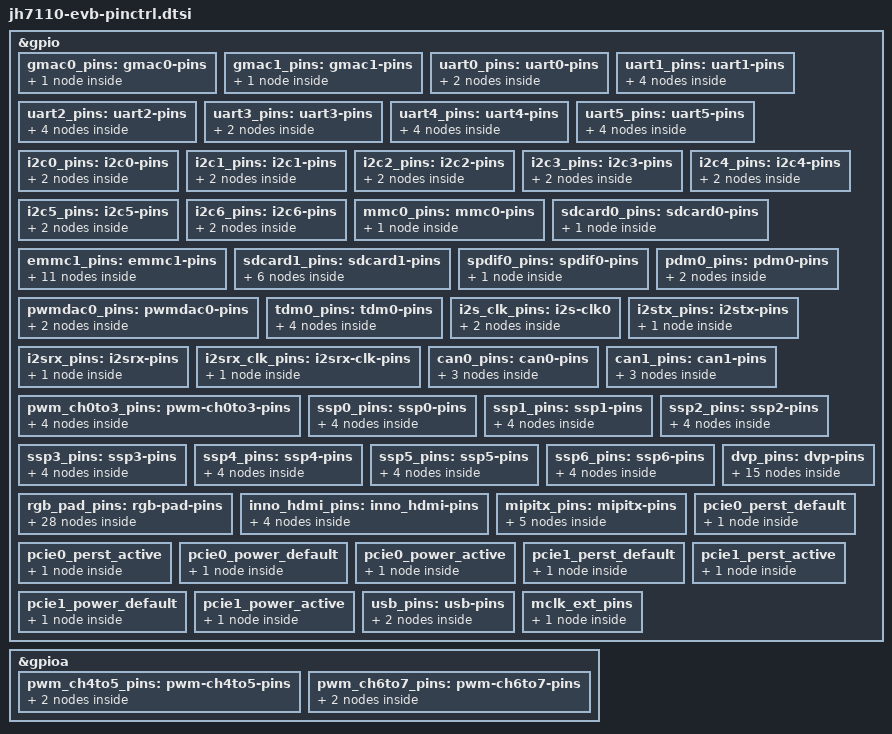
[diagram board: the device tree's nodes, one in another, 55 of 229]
// SPDX-License-Identifier: GPL-2.0 OR MIT
/*
 * Copyright (C) 2022 StarFive Technology Co., Ltd.
 */

#include <dt-bindings/gpio/gpio.h>
#include <dt-bindings/pinctrl/starfive,jh7110-pinfunc.h>

&gpio {
	gmac0_pins: gmac0-pins {
		gmac0-pins-reset {
			starfive,pins = <PAD_GPIO13>;
			starfive,pinmux = <PAD_GPIO13_FUNC_SEL 0>;
			starfive,pin-ioconfig = <IO(GPIO_IE(1) | (GPIO_PU(1)))>;
			starfive,pin-gpio-dout = <GPO_HIGH>;
			starfive,pin-gpio-doen = <OEN_LOW>;
		};
	};

	gmac1_pins: gmac1-pins {
		gmac1-pins0 {
			starfive,pins = <PAD_GMAC1_MDC>;
			starfive,pin-ioconfig = <IO(GPIO_IE(1)|GPIO_SMT(1) | GPIO_DS(3))>;
			starfive,pin-syscon = <PADCFG_PAD_GMAC1_MDC_SYSCON IO_3_3V>;
		};
	};

	uart0_pins: uart0-pins {
		uart0-pins-tx {
			starfive,pins = <PAD_GPIO5>;
			starfive,pin-ioconfig = <IO(GPIO_IE(1) | GPIO_DS(3))>;
			starfive,pin-gpio-dout = <GPO_UART0_SOUT>;
			starfive,pin-gpio-doen = <OEN_LOW>;
		};

		uart0-pins-rx {
			starfive,pins = <PAD_GPIO6>;
			starfive,pinmux = <PAD_GPIO6_FUNC_SEL 0>;
			starfive,pin-ioconfig = <IO(GPIO_IE(1) | GPIO_PU(1))>;
			starfive,pin-gpio-doen = <OEN_HIGH>;
			starfive,pin-gpio-din =  <GPI_UART0_SIN>;
		};
	};

	uart1_pins: uart1-pins {
		uart1-pins-tx {
			starfive,pins = <PAD_GPIO30>;
			starfive,pinmux = <PAD_GPIO30_FUNC_SEL 0>;
			starfive,pin-ioconfig = <IO(GPIO_IE(1) | GPIO_DS(3))>;
			starfive,pin-gpio-dout = <GPO_UART1_SOUT>;
			starfive,pin-gpio-doen = <OEN_LOW>;
		};

		uart1-pins-rx {
			starfive,pins = <PAD_GPIO31>;
			starfive,pinmux = <PAD_GPIO31_FUNC_SEL 0>;
			starfive,pin-ioconfig = <IO(GPIO_IE(1) | GPIO_PU(1))>;
			starfive,pin-gpio-doen = <OEN_HIGH>;
			starfive,pin-gpio-din =  <GPI_UART1_SIN>;
		};

		uart1-pins-cts {
			starfive,pins = <PAD_GPIO29>;
			starfive,pinmux = <PAD_GPIO29_FUNC_SEL 0>;
			starfive,pin-ioconfig = <IO(GPIO_IE(1))>;
			starfive,pin-gpio-doen = <OEN_HIGH>;
			starfive,pin-gpio-din =  <GPI_UART1_CTS_N>;
		};

		uart1-pins-rts {
			starfive,pins = <PAD_GPIO27>;
			starfive,pinmux = <PAD_GPIO27_FUNC_SEL 0>;
			starfive,pin-ioconfig = <IO(GPIO_IE(1))>;
			starfive,pin-gpio-dout = <GPO_UART1_RTS_N>;
			starfive,pin-gpio-doen = <OEN_LOW>;
		};
	};

	uart2_pins: uart2-pins {
		uart2-pins-tx {
			starfive,pins = <PAD_GPIO30>;
			starfive,pinmux = <PAD_GPIO30_FUNC_SEL 0>;
			starfive,pin-ioconfig = <IO(GPIO_IE(1) | GPIO_DS(3))>;
			starfive,pin-gpio-dout = <GPO_UART2_SOUT>;
			starfive,pin-gpio-doen = <OEN_LOW>;
		};

		uart2-pins-rx {
			starfive,pins = <PAD_GPIO31>;
			starfive,pinmux = <PAD_GPIO31_FUNC_SEL 0>;
			starfive,pin-ioconfig = <IO(GPIO_IE(1) | GPIO_PU(1))>;
			starfive,pin-gpio-doen = <OEN_HIGH>;
			starfive,pin-gpio-din =  <GPI_UART2_SIN>;
		};

		uart2-pins-cts {
			starfive,pins = <PAD_GPIO29>;
			starfive,pinmux = <PAD_GPIO29_FUNC_SEL 0>;
			starfive,pin-ioconfig = <IO(GPIO_IE(1))>;
			starfive,pin-gpio-doen = <OEN_HIGH>;
			starfive,pin-gpio-din =  <GPI_UART2_CTS_N>;
		};

		uart2-pins-rts {
			starfive,pins = <PAD_GPIO27>;
			starfive,pinmux = <PAD_GPIO27_FUNC_SEL 0>;
			starfive,pin-ioconfig = <IO(GPIO_IE(1))>;
			starfive,pin-gpio-dout = <GPO_UART2_RTS_N>;
			starfive,pin-gpio-doen = <OEN_LOW>;
		};
	};

	uart3_pins: uart3-pins {
		uart3-pins-tx {
			starfive,pins = <PAD_GPIO30>;
			starfive,pinmux = <PAD_GPIO30_FUNC_SEL 0>;
			starfive,pin-ioconfig = <IO(GPIO_IE(1) | GPIO_DS(3))>;
			starfive,pin-gpio-dout = <GPO_UART3_SOUT>;
			starfive,pin-gpio-doen = <OEN_LOW>;
		};

		uart3-pins-rx {
			starfive,pins = <PAD_GPIO31>;
			starfive,pinmux = <PAD_GPIO31_FUNC_SEL 0>;
			starfive,pin-ioconfig = <IO(GPIO_IE(1) | GPIO_PU(1))>;
			starfive,pin-gpio-doen = <OEN_HIGH>;
			starfive,pin-gpio-din =  <GPI_UART3_SIN>;
		};
	};

	uart4_pins: uart4-pins {
		uart4-pins-tx {
			starfive,pins = <PAD_GPIO30>;
			starfive,pinmux = <PAD_GPIO30_FUNC_SEL 0>;
			starfive,pin-ioconfig = <IO(GPIO_IE(1) | GPIO_DS(3))>;
			starfive,pin-gpio-dout = <GPO_UART4_SOUT>;
			starfive,pin-gpio-doen = <OEN_LOW>;
		};

		uart4-pins-rx {
			starfive,pins = <PAD_GPIO31>;
			starfive,pinmux = <PAD_GPIO31_FUNC_SEL 0>;
			starfive,pin-ioconfig = <IO(GPIO_IE(1) | GPIO_PU(1))>;
			starfive,pin-gpio-doen = <OEN_HIGH>;
			starfive,pin-gpio-din =  <GPI_UART4_SIN>;
		};

		uart4-pins-cts {
			starfive,pins = <PAD_GPIO29>;
			starfive,pinmux = <PAD_GPIO29_FUNC_SEL 0>;
			starfive,pin-ioconfig = <IO(GPIO_IE(1))>;
			starfive,pin-gpio-doen = <OEN_HIGH>;
			starfive,pin-gpio-din =  <GPI_UART4_CTS_N>;
		};

		uart4-pins-rts {
			starfive,pins = <PAD_GPIO27>;
			starfive,pinmux = <PAD_GPIO27_FUNC_SEL 0>;
			starfive,pin-ioconfig = <IO(GPIO_IE(1))>;
			starfive,pin-gpio-dout = <GPO_UART4_RTS_N>;
			starfive,pin-gpio-doen = <OEN_LOW>;
		};
	};

	uart5_pins: uart5-pins {
		uart5-pins-tx {
			starfive,pins = <PAD_GPIO30>;
			starfive,pinmux = <PAD_GPIO30_FUNC_SEL 0>;
			starfive,pin-ioconfig = <IO(GPIO_IE(1) | GPIO_DS(3))>;
			starfive,pin-gpio-dout = <GPO_UART5_SOUT>;
			starfive,pin-gpio-doen = <OEN_LOW>;
		};

		uart5-pins-rx {
			starfive,pins = <PAD_GPIO31>;
			starfive,pinmux = <PAD_GPIO31_FUNC_SEL 0>;
			starfive,pin-ioconfig = <IO(GPIO_IE(1) | GPIO_PU(1))>;
			starfive,pin-gpio-doen = <OEN_HIGH>;
			starfive,pin-gpio-din =  <GPI_UART5_SIN>;
		};

		uart5-pins-cts {
			starfive,pins = <PAD_GPIO29>;
			starfive,pinmux = <PAD_GPIO29_FUNC_SEL 0>;
			starfive,pin-ioconfig = <IO(GPIO_IE(1))>;
			starfive,pin-gpio-doen = <OEN_HIGH>;
			starfive,pin-gpio-din =  <GPI_UART5_CTS_N>;
		};

		uart5-pins-rts {
			starfive,pins = <PAD_GPIO27>;
			starfive,pinmux = <PAD_GPIO27_FUNC_SEL 0>;
			starfive,pin-ioconfig = <IO(GPIO_IE(1))>;
			starfive,pin-gpio-dout = <GPO_UART5_RTS_N>;
			starfive,pin-gpio-doen = <OEN_LOW>;
		};
	};

	i2c0_pins: i2c0-pins {
		i2c0-pins-scl {
			starfive,pins = <PAD_GPIO57>;
			starfive,pinmux = <PAD_GPIO57_FUNC_SEL 0>;
			starfive,pin-ioconfig = <IO(GPIO_IE(1) | (GPIO_PU(1)))>;
			starfive,pin-gpio-dout = <GPO_LOW>;
			starfive,pin-gpio-doen = <OEN_I2C0_IC_CLK_OE>;
			starfive,pin-gpio-din =  <GPI_I2C0_IC_CLK_IN_A>;
		};

		i2c0-pins-sda {
			starfive,pins = <PAD_GPIO58>;
			starfive,pinmux = <PAD_GPIO58_FUNC_SEL 0>;
			starfive,pin-ioconfig = <IO(GPIO_IE(1) | (GPIO_PU(1)))>;
			starfive,pin-gpio-dout = <GPO_LOW>;
			starfive,pin-gpio-doen = <OEN_I2C0_IC_DATA_OE>;
			starfive,pin-gpio-din =  <GPI_I2C0_IC_DATA_IN_A>;
		};
	};

	i2c1_pins: i2c1-pins {
		i2c1-pins-scl {
			starfive,pins = <PAD_GPIO49>;
			starfive,pinmux = <PAD_GPIO49_FUNC_SEL 0>;
			starfive,pin-ioconfig = <IO(GPIO_IE(1) | (GPIO_PU(1)))>;
			starfive,pin-gpio-dout = <GPO_LOW>;
			starfive,pin-gpio-doen = <OEN_I2C1_IC_CLK_OE>;
			starfive,pin-gpio-din =  <GPI_I2C1_IC_CLK_IN_A>;
		};

		i2c1-pins-sda {
			starfive,pins = <PAD_GPIO50>;
			starfive,pinmux = <PAD_GPIO50_FUNC_SEL 0>;
			starfive,pin-ioconfig = <IO(GPIO_IE(1) | (GPIO_PU(1)))>;
			starfive,pin-gpio-dout = <GPO_LOW>;
			starfive,pin-gpio-doen = <OEN_I2C1_IC_DATA_OE>;
			starfive,pin-gpio-din =  <GPI_I2C1_IC_DATA_IN_A>;
		};
	};

	i2c2_pins: i2c2-pins {
		i2c2-pins-scl {
			starfive,pins = <PAD_GPIO11>;
			starfive,pinmux = <PAD_GPIO11_FUNC_SEL 0>;
			starfive,pin-ioconfig = <IO(GPIO_IE(1) | (GPIO_PU(1)))>;
			starfive,pin-gpio-dout = <GPO_LOW>;
			starfive,pin-gpio-doen = <OEN_I2C2_IC_CLK_OE>;
			starfive,pin-gpio-din =  <GPI_I2C2_IC_CLK_IN_A>;
		};

		i2c2-pins-sda {
			starfive,pins = <PAD_GPIO9>;
			starfive,pinmux = <PAD_GPIO9_FUNC_SEL 0>;
			starfive,pin-ioconfig = <IO(GPIO_IE(1) | (GPIO_PU(1)))>;
			starfive,pin-gpio-dout = <GPO_LOW>;
			starfive,pin-gpio-doen = <OEN_I2C2_IC_DATA_OE>;
			starfive,pin-gpio-din =  <GPI_I2C2_IC_DATA_IN_A>;
		};
	};

	i2c3_pins: i2c3-pins {
		i2c3-pins-scl {
			starfive,pins = <PAD_GPIO51>;
			starfive,pinmux = <PAD_GPIO51_FUNC_SEL 0>;
			starfive,pin-ioconfig = <IO(GPIO_IE(1) | (GPIO_PU(1)))>;
			starfive,pin-gpio-dout = <GPO_LOW>;
			starfive,pin-gpio-doen = <OEN_I2C3_IC_CLK_OE>;
			starfive,pin-gpio-din =  <GPI_I2C3_IC_CLK_IN_A>;
		};

		i2c3-pins-sda {
			starfive,pins = <PAD_GPIO52>;
			starfive,pinmux = <PAD_GPIO52_FUNC_SEL 0>;
			starfive,pin-ioconfig = <IO(GPIO_IE(1) | (GPIO_PU(1)))>;
			starfive,pin-gpio-dout = <GPO_LOW>;
			starfive,pin-gpio-doen = <OEN_I2C3_IC_DATA_OE>;
			starfive,pin-gpio-din =  <GPI_I2C3_IC_DATA_IN_A>;
		};
	};

	i2c4_pins: i2c4-pins {
		i2c4-pins-scl {
			starfive,pins = <PAD_GPIO18>;
			starfive,pinmux = <PAD_GPIO18_FUNC_SEL 0>;
			starfive,pin-ioconfig = <IO(GPIO_IE(1) | (GPIO_PU(1)))>;
			starfive,pin-gpio-dout = <GPO_LOW>;
			starfive,pin-gpio-doen = <OEN_I2C4_IC_CLK_OE>;
			starfive,pin-gpio-din =  <GPI_I2C4_IC_CLK_IN_A>;
		};

		i2c4-pins-sda {
			starfive,pins = <PAD_GPIO12>;
			starfive,pinmux = <PAD_GPIO12_FUNC_SEL 0>;
			starfive,pin-ioconfig = <IO(GPIO_IE(1) | (GPIO_PU(1)))>;
			starfive,pin-gpio-dout = <GPO_LOW>;
			starfive,pin-gpio-doen = <OEN_I2C4_IC_DATA_OE>;
			starfive,pin-gpio-din =  <GPI_I2C4_IC_DATA_IN_A>;
		};
	};

	i2c5_pins: i2c5-pins {
		i2c5-pins-scl {
			starfive,pins = <PAD_GPIO19>;
			starfive,pinmux = <PAD_GPIO19_FUNC_SEL 0>;
			starfive,pin-ioconfig = <IO(GPIO_IE(1) | (GPIO_PU(1)))>;
			starfive,pin-gpio-dout = <GPO_LOW>;
			starfive,pin-gpio-doen = <OEN_I2C5_IC_CLK_OE>;
			starfive,pin-gpio-din =  <GPI_I2C5_IC_CLK_IN_A>;
		};

		i2c5-pins-sda {
			starfive,pins = <PAD_GPIO20>;
			starfive,pinmux = <PAD_GPIO20_FUNC_SEL 0>;
			starfive,pin-ioconfig = <IO(GPIO_IE(1) | (GPIO_PU(1)))>;
			starfive,pin-gpio-dout = <GPO_LOW>;
			starfive,pin-gpio-doen = <OEN_I2C5_IC_DATA_OE>;
			starfive,pin-gpio-din =  <GPI_I2C5_IC_DATA_IN_A>;
		};
	};

	i2c6_pins: i2c6-pins {
		i2c6-pins-scl {
			starfive,pins = <PAD_GPIO16>;
			starfive,pinmux = <PAD_GPIO16_FUNC_SEL 0>;
			starfive,pin-ioconfig = <IO(GPIO_IE(1) | (GPIO_PU(1)))>;
			starfive,pin-gpio-dout = <GPO_LOW>;
			starfive,pin-gpio-doen = <OEN_I2C6_IC_CLK_OE>;
			starfive,pin-gpio-din =  <GPI_I2C6_IC_CLK_IN_A>;
		};

		i2c6-pins-sda {
			starfive,pins = <PAD_GPIO17>;
			starfive,pinmux = <PAD_GPIO17_FUNC_SEL 0>;
			starfive,pin-ioconfig = <IO(GPIO_IE(1) | (GPIO_PU(1)))>;
			starfive,pin-gpio-dout = <GPO_LOW>;
			starfive,pin-gpio-doen = <OEN_I2C6_IC_DATA_OE>;
			starfive,pin-gpio-din =  <GPI_I2C6_IC_DATA_IN_A>;
		};
	};

	mmc0_pins: mmc0-pins {
		 mmc0-pins-rest {
			starfive,pins = <PAD_GPIO22>;
			starfive,pinmux = <PAD_GPIO22_FUNC_SEL 0>;
			starfive,pin-ioconfig = <IO(GPIO_IE(1) | (GPIO_PU(1)))>;
			starfive,pin-gpio-dout = <GPO_SDIO0_RST_N>;
			starfive,pin-gpio-doen = <OEN_LOW>;
		};
	};

	sdcard0_pins: sdcard0-pins {
		 sdcard0-pins-rest {
			starfive,pins = <PAD_GPIO24>;
			starfive,pinmux = <PAD_GPIO24_FUNC_SEL 0>;
			starfive,pin-ioconfig = <IO(GPIO_IE(1) | (GPIO_PU(1)))>;
			starfive,pin-gpio-dout = <GPO_SDIO0_RST_N>;
			starfive,pin-gpio-doen = <OEN_LOW>;
		};
	};

	emmc1_pins: emmc1-pins {
		emmc1-pins0-rest {
			starfive,pins = <PAD_GPIO51>;
			starfive,pinmux = <PAD_GPIO51_FUNC_SEL 0>;
			starfive,pin-ioconfig = <IO(GPIO_IE(1) | (GPIO_PU(1)))>;
			starfive,pin-gpio-dout = <GPO_SDIO1_RST_N>;
			starfive,pin-gpio-doen = <OEN_LOW>;
		};

		emmc1-pins1 {
			starfive,pins = <PAD_GPIO38>;
			starfive,pinmux = <PAD_GPIO38_FUNC_SEL 0>;
			starfive,pin-ioconfig = <IO(GPIO_IE(1) | (GPIO_PU(1)))>;
			starfive,pin-gpio-dout = <GPO_SDIO1_CCLK_OUT>;
			starfive,pin-gpio-doen = <OEN_LOW>;
		};

		emmc1-pins2 {
			starfive,pins = <PAD_GPIO36>;
			starfive,pinmux = <PAD_GPIO36_FUNC_SEL 0>;
			starfive,pin-ioconfig = <IO(GPIO_IE(1) | (GPIO_PU(1)))>;
			starfive,pin-gpio-dout = <GPO_SDIO1_CCMD_OUT>;
			starfive,pin-gpio-doen = <OEN_SDIO1_CCMD_OUT_EN>;
			starfive,pin-gpio-din =  <GPI_SDIO1_CCMD_IN>;
		};

		emmc1-pins3 {
			starfive,pins = <PAD_GPIO43>;
			starfive,pinmux = <PAD_GPIO43_FUNC_SEL 0>;
			starfive,pin-ioconfig = <IO(GPIO_IE(1) | (GPIO_PU(1)))>;
			starfive,pin-gpio-dout = <GPO_SDIO1_CDATA_OUT_0>;
			starfive,pin-gpio-doen = <OEN_SDIO1_CDATA_OUT_EN_0>;
			starfive,pin-gpio-din =  <GPI_SDIO1_CDATA_IN_0>;
		};

		emmc1-pins4 {
			starfive,pins = <PAD_GPIO48>;
			starfive,pinmux = <PAD_GPIO48_FUNC_SEL 0>;
			starfive,pin-ioconfig = <IO(GPIO_IE(1) | (GPIO_PU(1)))>;
			starfive,pin-gpio-dout = <GPO_SDIO1_CDATA_OUT_1>;
			starfive,pin-gpio-doen = <OEN_SDIO1_CDATA_OUT_EN_1>;
			starfive,pin-gpio-din =  <GPI_SDIO1_CDATA_IN_1>;
		};

		emmc1-pins5 {
			starfive,pins = <PAD_GPIO53>;
			starfive,pinmux = <PAD_GPIO53_FUNC_SEL 0>;
			starfive,pin-ioconfig = <IO(GPIO_IE(1) | (GPIO_PU(1)))>;
			starfive,pin-gpio-dout = <GPO_SDIO1_CDATA_OUT_2>;
			starfive,pin-gpio-doen = <OEN_SDIO1_CDATA_OUT_EN_2>;
			starfive,pin-gpio-din =  <GPI_SDIO1_CDATA_IN_2>;
		};

		emmc1-pins6 {
			starfive,pins = <PAD_GPIO63>;
			starfive,pinmux = <PAD_GPIO63_FUNC_SEL 0>;
			starfive,pin-ioconfig = <IO(GPIO_IE(1) | (GPIO_PU(1)))>;
			starfive,pin-gpio-dout = <GPO_SDIO1_CDATA_OUT_3>;
			starfive,pin-gpio-doen = <OEN_SDIO1_CDATA_OUT_EN_3>;
			starfive,pin-gpio-din =  <GPI_SDIO1_CDATA_IN_3>;
		};

		emmc1-pins7 {
			starfive,pins = <PAD_GPIO52>;
			starfive,pinmux = <PAD_GPIO52_FUNC_SEL 0>;
			starfive,pin-ioconfig = <IO(GPIO_IE(1) | (GPIO_PU(1)))>;
			starfive,pin-gpio-dout = <GPO_SDIO1_CDATA_OUT_4>;
			starfive,pin-gpio-doen = <OEN_SDIO1_CDATA_OUT_EN_4>;
			starfive,pin-gpio-din =  <GPI_SDIO1_CDATA_IN_4>;
		};

		emmc1-pins8 {
			starfive,pins = <PAD_GPIO39>;
			starfive,pinmux = <PAD_GPIO39_FUNC_SEL 0>;
			starfive,pin-ioconfig = <IO(GPIO_IE(1) | (GPIO_PU(1)))>;
			starfive,pin-gpio-dout = <GPO_SDIO1_CDATA_OUT_5>;
			starfive,pin-gpio-doen = <OEN_SDIO1_CDATA_OUT_EN_5>;
			starfive,pin-gpio-din =  <GPI_SDIO1_CDATA_IN_5>;
		};

		emmc1-pins9 {
			starfive,pins = <PAD_GPIO46>;
			starfive,pinmux = <PAD_GPIO46_FUNC_SEL 0>;
			starfive,pin-ioconfig = <IO(GPIO_IE(1) | (GPIO_PU(1)))>;
			starfive,pin-gpio-dout = <GPO_SDIO1_CDATA_OUT_6>;
			starfive,pin-gpio-doen = <OEN_SDIO1_CDATA_OUT_EN_6>;
			starfive,pin-gpio-din =  <GPI_SDIO1_CDATA_IN_6>;
		};

		emmc1-pins10 {
			starfive,pins = <PAD_GPIO47>;
			starfive,pinmux = <PAD_GPIO47_FUNC_SEL 0>;
			starfive,pin-ioconfig = <IO(GPIO_IE(1) | (GPIO_PU(1)))>;
			starfive,pin-gpio-dout = <GPO_SDIO1_CDATA_OUT_7>;
			starfive,pin-gpio-doen = <OEN_SDIO1_CDATA_OUT_EN_7>;
			starfive,pin-gpio-din =  <GPI_SDIO1_CDATA_IN_7>;
		};
	};

	sdcard1_pins: sdcard1-pins {
		sdcard1-pins0 {
			starfive,pins = <PAD_GPIO56>;
			starfive,pinmux = <PAD_GPIO56_FUNC_SEL 0>;
			starfive,pin-ioconfig = <IO(GPIO_IE(1) | (GPIO_PU(1)))>;
			starfive,pin-gpio-dout = <GPO_SDIO1_CCLK_OUT>;
			starfive,pin-gpio-doen = <OEN_LOW>;
		};

		sdcard1-pins1 {
			starfive,pins = <PAD_GPIO50>;
			starfive,pinmux = <PAD_GPIO50_FUNC_SEL 0>;
			starfive,pin-ioconfig = <IO(GPIO_IE(1) | (GPIO_PU(1)))>;
			starfive,pin-gpio-dout = <GPO_SDIO1_CCMD_OUT>;
			starfive,pin-gpio-doen = <OEN_SDIO1_CCMD_OUT_EN>;
			starfive,pin-gpio-din =  <GPI_SDIO1_CCMD_IN>;
		};

		sdcard1-pins2 {
			starfive,pins = <PAD_GPIO49>;
			starfive,pinmux = <PAD_GPIO49_FUNC_SEL 0>;
			starfive,pin-ioconfig = <IO(GPIO_IE(1) | (GPIO_PU(1)))>;
			starfive,pin-gpio-dout = <GPO_SDIO1_CDATA_OUT_0>;
			starfive,pin-gpio-doen = <OEN_SDIO1_CDATA_OUT_EN_0>;
			starfive,pin-gpio-din =  <GPI_SDIO1_CDATA_IN_0>;
		};

		sdcard1-pins3 {
			starfive,pins = <PAD_GPIO45>;
			starfive,pinmux = <PAD_GPIO45_FUNC_SEL 0>;
			starfive,pin-ioconfig = <IO(GPIO_IE(1) | (GPIO_PU(1)))>;
			starfive,pin-gpio-dout = <GPO_SDIO1_CDATA_OUT_1>;
			starfive,pin-gpio-doen = <OEN_SDIO1_CDATA_OUT_EN_1>;
			starfive,pin-gpio-din =  <GPI_SDIO1_CDATA_IN_1>;
		};

		sdcard1-pins4 {
			starfive,pins = <PAD_GPIO62>;
			starfive,pinmux = <PAD_GPIO62_FUNC_SEL 0>;
			starfive,pin-ioconfig = <IO(GPIO_IE(1) | (GPIO_PU(1)))>;
			starfive,pin-gpio-dout = <GPO_SDIO1_CDATA_OUT_2>;
			starfive,pin-gpio-doen = <OEN_SDIO1_CDATA_OUT_EN_2>;
			starfive,pin-gpio-din =  <GPI_SDIO1_CDATA_IN_2>;
		};

		sdcard1-pins5 {
			starfive,pins = <PAD_GPIO40>;
			starfive,pinmux = <PAD_GPIO40_FUNC_SEL 0>;
			starfive,pin-ioconfig = <IO(GPIO_IE(1) | (GPIO_PU(1)))>;
			starfive,pin-gpio-dout = <GPO_SDIO1_CDATA_OUT_3>;
			starfive,pin-gpio-doen = <OEN_SDIO1_CDATA_OUT_EN_3>;
			starfive,pin-gpio-din =  <GPI_SDIO1_CDATA_IN_3>;
		};
	};

	spdif0_pins: spdif0-pins {
		spdif0-pins {
			starfive,pins = <PAD_GPIO57>;
			starfive,pinmux = <PAD_GPIO57_FUNC_SEL 0>;
			starfive,pin-ioconfig = <IO(GPIO_IE(1)|(GPIO_PU(1)))>;
			starfive,pin-gpio-dout = <GPO_SPDIF0_SPDIFO>;
			starfive,pin-gpio-doen = <OEN_LOW>;
		};
	};

	pwmdac0_pins: pwmdac0-pins {
		pwmdac0-pins-left {
			starfive,pins = <PAD_GPIO57>;
			starfive,pinmux = <PAD_GPIO57_FUNC_SEL 0>;
			starfive,pin-ioconfig = <IO(GPIO_IE(1) | (GPIO_PU(1)))>;
			starfive,pin-gpio-dout = <GPO_PWMDAC0_LEFT_OUTPUT>;
			starfive,pin-gpio-doen = <OEN_LOW>;
		};

		pwmdac0-pins-right {
			starfive,pins = <PAD_GPIO42>;
			starfive,pinmux = <PAD_GPIO42_FUNC_SEL 0>;
			starfive,pin-ioconfig = <IO(GPIO_IE(1) | (GPIO_PU(1)))>;
			starfive,pin-gpio-dout = <GPO_PWMDAC0_RIGHT_OUTPUT>;
			starfive,pin-gpio-doen = <OEN_LOW>;
		};
	};

	pdm0_pins: pdm0-pins {
		pdm0-pins-mclk {
			starfive,pins = <PAD_GPIO54>;
			starfive,pinmux = <PAD_GPIO54_FUNC_SEL 0>;
			starfive,pin-ioconfig = <IO(GPIO_IE(1))>;
			starfive,pin-gpio-dout = <GPO_PDM_4MIC0_DMIC_MCLK>;
			starfive,pin-gpio-doen = <OEN_LOW>;
		};

		pdm0-pins-sdin {
			starfive,pins = <PAD_GPIO60>;
			starfive,pinmux = <PAD_GPIO60_FUNC_SEL 0>;
			starfive,pin-ioconfig = <IO(GPIO_IE(1))>;
			starfive,pin-gpio-doen = <OEN_HIGH>;
			starfive,pin-gpio-din =  <GPI_PDM_4MIC0_DMIC0_DIN>;
		};
	};

	tdm0_pins: tdm0-pins {
		tdm0-pins-tx {
			starfive,pins = <PAD_GPIO44>;
			starfive,pinmux = <PAD_GPIO44_FUNC_SEL 0>;
			starfive,pin-ioconfig = <IO(GPIO_IE(1))>;
			starfive,pin-gpio-dout = <GPO_TDM0_PCM_TXD>;
			starfive,pin-gpio-doen = <OEN_LOW>;
		};

		tdm0-pins-rx {
			starfive,pins = <PAD_GPIO61>;
			starfive,pinmux = <PAD_GPIO61_FUNC_SEL 0>;
			starfive,pin-ioconfig = <IO(GPIO_IE(1))>;
			starfive,pin-gpio-doen = <OEN_HIGH>;
			starfive,pin-gpio-din =  <GPI_TDM0_PCM_RXD>;
		};

		tdm0-pins-sync {
			starfive,pins = <PAD_GPIO63>;
			starfive,pinmux = <PAD_GPIO63_FUNC_SEL 0>;
			starfive,pin-ioconfig = <IO(GPIO_IE(1))>;
			starfive,pin-gpio-doen = <OEN_HIGH>;
			starfive,pin-gpio-din = <GPI_TDM0_PCM_SYNCIN>;
		};

		tdm0-pins-pcmclk {
			starfive,pins = <PAD_GPIO38>;
			starfive,pinmux = <PAD_GPIO38_FUNC_SEL 0>;
			starfive,pin-ioconfig = <IO(GPIO_IE(1))>;
			starfive,pin-gpio-doen = <OEN_HIGH>;
			starfive,pin-gpio-din = <GPI_TDM0_CLK_SLV>;
		};
	};

	i2s_clk_pins: i2s-clk0 {
		i2s-clk0_bclk {
			starfive,pins = <PAD_GPIO38>;
			starfive,pinmux = <PAD_GPIO38_FUNC_SEL 0>;
			starfive,pin-ioconfig = <IO(GPIO_IE(1))>;
			starfive,pin-gpio-din = <GPI_I2STX0_BCLK_SLV GPI_I2SRX0_BCLK_SLV>;
			starfive,pin-gpio-doen = <OEN_HIGH>;
		};

		i2s-clk0_lrclk {
			starfive,pins = <PAD_GPIO63>;
			starfive,pinmux = <PAD_GPIO63_FUNC_SEL 0>;
			starfive,pin-ioconfig = <IO(GPIO_IE(1))>;
			starfive,pin-gpio-din = <GPI_I2STX0_LRCK_SLV GPI_I2SRX0_LRCK_SLV>;
			starfive,pin-gpio-doen = <OEN_HIGH>;
		};
	};

	i2stx_pins: i2stx-pins {
		i2stx-pins0 {
			starfive,pins = <PAD_GPIO44>;
			starfive,pinmux = <PAD_GPIO44_FUNC_SEL 0>;
			starfive,pin-ioconfig = <IO(GPIO_IE(1))>;
			starfive,pin-gpio-dout = <GPO_I2STX_4CH1_SDO0>;
			starfive,pin-gpio-doen = <OEN_LOW>;
		};
	};

	i2srx_pins: i2srx-pins {
		i2srx-pins0 {
			starfive,pins = <PAD_GPIO61>;
			starfive,pinmux = <PAD_GPIO61_FUNC_SEL 0>;
			starfive,pin-ioconfig = <IO(GPIO_IE(1))>;
			starfive,pin-gpio-doen = <OEN_HIGH>;
			starfive,pin-gpio-din =  <GPI_I2SRX0_EXT_SDIN0>;
		};
	};

	i2srx_clk_pins: i2srx-clk-pins {
		i2srx-clk-pins-mclk {
			starfive,pins = <PAD_GPIO58>;
			starfive,pinmux = <PAD_GPIO58_FUNC_SEL 0>;
			starfive,pin-ioconfig = <IO(GPIO_IE(1))>;
			starfive,pin-gpio-dout = <GPO_CRG0_MCLK_OUT>;
			starfive,pin-gpio-doen = <OEN_LOW>;
		};
	};

	can0_pins: can0-pins {
		can0-pins0 {
			starfive,pins = <PAD_GPIO30>;
			starfive,pinmux = <PAD_GPIO30_FUNC_SEL 0>;
			starfive,pin-ioconfig = <IO(GPIO_IE(1))>;
			starfive,pin-gpio-dout = <GPO_CAN0_CTRL_TXD>;
			starfive,pin-gpio-doen = <OEN_LOW>;
		};

		can0-pins1 {
			starfive,pins = <PAD_GPIO31>;
			starfive,pinmux = <PAD_GPIO31_FUNC_SEL 0>;
			starfive,pin-ioconfig = <IO(GPIO_IE(1))>;
			starfive,pin-gpio-doen = <OEN_HIGH>;
			starfive,pin-gpio-din =  <GPI_CAN0_CTRL_RXD>;
		};

		can0-pins2 {
			starfive,pins = <PAD_GPIO32>;
			starfive,pinmux = <PAD_GPIO32_FUNC_SEL 0>;
			starfive,pin-ioconfig = <IO(GPIO_IE(1))>;
			starfive,pin-gpio-dout = <GPO_CAN0_CTRL_STBY>;
			starfive,pin-gpio-doen = <OEN_LOW>;
		};
	};

	can1_pins: can1-pins {
		can1-pins0 {
			starfive,pins = <PAD_GPIO29>;
			starfive,pinmux = <PAD_GPIO29_FUNC_SEL 0>;
			starfive,pin-ioconfig = <IO(GPIO_IE(1)| GPIO_DS(3))>;
			starfive,pin-gpio-dout = <GPO_CAN1_CTRL_TXD>;
			starfive,pin-gpio-doen = <OEN_LOW>;
		};

		can1-pins1 {
			starfive,pins = <PAD_GPIO27>;
			starfive,pinmux = <PAD_GPIO27_FUNC_SEL 0>;
			starfive,pin-ioconfig = <IO(GPIO_IE(1)| GPIO_DS(3))>;
			starfive,pin-gpio-doen = <OEN_HIGH>;
			starfive,pin-gpio-din =  <GPI_CAN1_CTRL_RXD>;
		};

		can1-pins2 {
			starfive,pins = <PAD_GPIO45>;
			starfive,pinmux = <PAD_GPIO45_FUNC_SEL 0>;
			starfive,pin-ioconfig = <IO(GPIO_IE(1))>;
			starfive,pin-gpio-dout = <GPO_CAN1_CTRL_STBY>;
			starfive,pin-gpio-doen = <OEN_LOW>;
		};
	};

	pwm_ch0to3_pins: pwm-ch0to3-pins {
		pwm_ch0-pins {
			starfive,pins = <PAD_GPIO45>;
			starfive,pinmux = <PAD_GPIO45_FUNC_SEL 0>;
			starfive,pin-ioconfig = <IO(GPIO_IE(1))>;
			starfive,pin-gpio-dout = <GPO_PTC0_PWM_0>;
			starfive,pin-gpio-doen = <OEN_PTC0_PWM_0_OE_N>;
		};

		pwm_ch1-pins {
			starfive,pins = <PAD_GPIO46>;
			starfive,pinmux = <PAD_GPIO46_FUNC_SEL 0>;
			starfive,pin-ioconfig = <IO(GPIO_IE(1))>;
			starfive,pin-gpio-dout = <GPO_PTC0_PWM_1>;
			starfive,pin-gpio-doen = <OEN_PTC0_PWM_1_OE_N>;
		};

		pwm_ch2-pins {
			starfive,pins = <PAD_GPIO47>;
			starfive,pinmux = <PAD_GPIO47_FUNC_SEL 0>;
			starfive,pin-ioconfig = <IO(GPIO_IE(1))>;
			starfive,pin-gpio-dout = <GPO_PTC0_PWM_2>;
			starfive,pin-gpio-doen = <OEN_PTC0_PWM_2_OE_N>;
		};

		pwm_ch3-pins {
			starfive,pins = <PAD_GPIO48>;
			starfive,pinmux = <PAD_GPIO48_FUNC_SEL 0>;
			starfive,pin-ioconfig = <IO(GPIO_IE(1))>;
			starfive,pin-gpio-dout = <GPO_PTC0_PWM_3>;
			starfive,pin-gpio-doen = <OEN_PTC0_PWM_3_OE_N>;
		};
	};

	ssp0_pins: ssp0-pins {
		ssp0-pins_tx {
			starfive,pins = <PAD_GPIO38>;
			starfive,pinmux = <PAD_GPIO38_FUNC_SEL 0>;
			starfive,pin-ioconfig = <IO(GPIO_IE(1))>;
			starfive,pin-gpio-dout = <GPO_SPI0_SSPTXD>;
			starfive,pin-gpio-doen = <OEN_LOW>;
		};

		ssp0-pins_rx {
			starfive,pins = <PAD_GPIO39>;
			starfive,pinmux = <PAD_GPIO39_FUNC_SEL 0>;
			starfive,pin-ioconfig = <IO(GPIO_IE(1))>;
			starfive,pin-gpio-doen = <OEN_HIGH>;
			starfive,pin-gpio-din =  <GPI_SPI0_SSPRXD>;
		};

		ssp0-pins_clk {
			starfive,pins = <PAD_GPIO36>;
			starfive,pinmux = <PAD_GPIO36_FUNC_SEL 0>;
			starfive,pin-ioconfig = <IO(GPIO_IE(1))>;
			starfive,pin-gpio-dout = <GPO_SPI0_SSPCLKOUT>;
			starfive,pin-gpio-doen = <OEN_LOW>;
		};

		ssp0-pins_cs {
			starfive,pins = <PAD_GPIO37>;
			starfive,pinmux = <PAD_GPIO37_FUNC_SEL 0>;
			starfive,pin-ioconfig = <IO(GPIO_IE(1))>;
			starfive,pin-gpio-dout = <GPO_SPI0_SSPFSSOUT>;
			starfive,pin-gpio-doen = <OEN_LOW>;
		};
	};

	ssp1_pins: ssp1-pins {
		ssp1-pins_tx {
			starfive,pins = <PAD_GPIO42>;
			starfive,pinmux = <PAD_GPIO42_FUNC_SEL 0>;
			starfive,pin-ioconfig = <IO(GPIO_IE(1))>;
			starfive,pin-gpio-dout = <GPO_SPI1_SSPTXD>;
			starfive,pin-gpio-doen = <OEN_LOW>;
		};

		ssp1-pins_rx {
			starfive,pins = <PAD_GPIO43>;
			starfive,pinmux = <PAD_GPIO43_FUNC_SEL 0>;
			starfive,pin-ioconfig = <IO(GPIO_IE(1))>;
			starfive,pin-gpio-doen = <OEN_HIGH>;
			starfive,pin-gpio-din =  <GPI_SPI1_SSPRXD>;
		};

		ssp1-pins_clk {
			starfive,pins = <PAD_GPIO40>;
			starfive,pinmux = <PAD_GPIO40_FUNC_SEL 0>;
			starfive,pin-ioconfig = <IO(GPIO_IE(1))>;
			starfive,pin-gpio-dout = <GPO_SPI1_SSPCLKOUT>;
			starfive,pin-gpio-doen = <OEN_LOW>;
		};

		ssp1-pins_cs {
			starfive,pins = <PAD_GPIO41>;
			starfive,pinmux = <PAD_GPIO41_FUNC_SEL 0>;
			starfive,pin-ioconfig = <IO(GPIO_IE(1))>;
			starfive,pin-gpio-dout = <GPO_SPI1_SSPFSSOUT>;
			starfive,pin-gpio-doen = <OEN_LOW>;
		};
	};

	ssp2_pins: ssp2-pins {
		ssp2-pins_tx {
			starfive,pins = <PAD_GPIO46>;
			starfive,pinmux = <PAD_GPIO46_FUNC_SEL 0>;
			starfive,pin-ioconfig = <IO(GPIO_IE(1))>;
			starfive,pin-gpio-dout = <GPO_SPI2_SSPTXD>;
			starfive,pin-gpio-doen = <OEN_LOW>;
		};

		ssp2-pins_rx {
			starfive,pins = <PAD_GPIO47>;
			starfive,pinmux = <PAD_GPIO47_FUNC_SEL 0>;
			starfive,pin-ioconfig = <IO(GPIO_IE(1))>;
			starfive,pin-gpio-doen = <OEN_HIGH>;
			starfive,pin-gpio-din =  <GPI_SPI2_SSPRXD>;
		};

		ssp2-pins_clk {
			starfive,pins = <PAD_GPIO44>;
			starfive,pinmux = <PAD_GPIO44_FUNC_SEL 0>;
			starfive,pin-ioconfig = <IO(GPIO_IE(1))>;
			starfive,pin-gpio-dout = <GPO_SPI2_SSPCLKOUT>;
			starfive,pin-gpio-doen = <OEN_LOW>;
		};

		ssp2-pins_cs {
			starfive,pins = <PAD_GPIO45>;
			starfive,pinmux = <PAD_GPIO45_FUNC_SEL 0>;
			starfive,pin-ioconfig = <IO(GPIO_IE(1))>;
			starfive,pin-gpio-dout = <GPO_SPI2_SSPFSSOUT>;
			starfive,pin-gpio-doen = <OEN_LOW>;
		};
	};

	ssp3_pins: ssp3-pins {
		ssp3-pins_tx {
			starfive,pins = <PAD_GPIO50>;
			starfive,pinmux = <PAD_GPIO50_FUNC_SEL 0>;
			starfive,pin-ioconfig = <IO(GPIO_IE(1))>;
			starfive,pin-gpio-dout = <GPO_SPI3_SSPTXD>;
			starfive,pin-gpio-doen = <OEN_LOW>;
		};

		ssp3-pins_rx {
			starfive,pins = <PAD_GPIO51>;
			starfive,pinmux = <PAD_GPIO51_FUNC_SEL 0>;
			starfive,pin-ioconfig = <IO(GPIO_IE(1))>;
			starfive,pin-gpio-doen = <OEN_HIGH>;
			starfive,pin-gpio-din =  <GPI_SPI3_SSPRXD>;
		};

		ssp3-pins_clk {
			starfive,pins = <PAD_GPIO48>;
			starfive,pinmux = <PAD_GPIO48_FUNC_SEL 0>;
			starfive,pin-ioconfig = <IO(GPIO_IE(1))>;
			starfive,pin-gpio-dout = <GPO_SPI3_SSPCLKOUT>;
			starfive,pin-gpio-doen = <OEN_LOW>;
		};

		ssp3-pins_cs {
			starfive,pins = <PAD_GPIO49>;
			starfive,pinmux = <PAD_GPIO49_FUNC_SEL 0>;
			starfive,pin-ioconfig = <IO(GPIO_IE(1))>;
			starfive,pin-gpio-dout = <GPO_SPI3_SSPFSSOUT>;
			starfive,pin-gpio-doen = <OEN_LOW>;
		};
	};

	ssp4_pins: ssp4-pins {
		ssp4-pins_tx {
			starfive,pins = <PAD_GPIO54>;
			starfive,pinmux = <PAD_GPIO54_FUNC_SEL 0>;
			starfive,pin-ioconfig = <IO(GPIO_IE(1))>;
			starfive,pin-gpio-dout = <GPO_SPI4_SSPTXD>;
			starfive,pin-gpio-doen = <OEN_LOW>;
		};

		ssp4-pins_rx {
			starfive,pins = <PAD_GPIO55>;
			starfive,pinmux = <PAD_GPIO55_FUNC_SEL 0>;
			starfive,pin-ioconfig = <IO(GPIO_IE(1))>;
			starfive,pin-gpio-doen = <OEN_HIGH>;
			starfive,pin-gpio-din =  <GPI_SPI4_SSPRXD>;
		};

		ssp4-pins_clk {
			starfive,pins = <PAD_GPIO52>;
			starfive,pinmux = <PAD_GPIO52_FUNC_SEL 0>;
			starfive,pin-ioconfig = <IO(GPIO_IE(1))>;
			starfive,pin-gpio-dout = <GPO_SPI4_SSPCLKOUT>;
			starfive,pin-gpio-doen = <OEN_LOW>;
		};

		ssp4-pins_cs {
			starfive,pins = <PAD_GPIO53>;
			starfive,pinmux = <PAD_GPIO53_FUNC_SEL 0>;
			starfive,pin-ioconfig = <IO(GPIO_IE(1))>;
			starfive,pin-gpio-dout = <GPO_SPI4_SSPFSSOUT>;
			starfive,pin-gpio-doen = <OEN_LOW>;
		};
	};

	ssp5_pins: ssp5-pins {
		ssp5-pins_tx {
			starfive,pins = <PAD_GPIO58>;
			starfive,pinmux = <PAD_GPIO58_FUNC_SEL 0>;
			starfive,pin-ioconfig = <IO(GPIO_IE(1))>;
			starfive,pin-gpio-dout = <GPO_SPI5_SSPTXD>;
			starfive,pin-gpio-doen = <OEN_LOW>;
		};

		ssp5-pins_rx {
			starfive,pins = <PAD_GPIO59>;
			starfive,pinmux = <PAD_GPIO59_FUNC_SEL 0>;
			starfive,pin-ioconfig = <IO(GPIO_IE(1))>;
			starfive,pin-gpio-doen = <OEN_HIGH>;
			starfive,pin-gpio-din =  <GPI_SPI5_SSPRXD>;
		};

		ssp5-pins_clk {
			starfive,pins = <PAD_GPIO56>;
			starfive,pinmux = <PAD_GPIO56_FUNC_SEL 0>;
			starfive,pin-ioconfig = <IO(GPIO_IE(1))>;
			starfive,pin-gpio-dout = <GPO_SPI5_SSPCLKOUT>;
			starfive,pin-gpio-doen = <OEN_LOW>;
		};

		ssp5-pins_cs {
			starfive,pins = <PAD_GPIO57>;
			starfive,pinmux = <PAD_GPIO57_FUNC_SEL 0>;
			starfive,pin-ioconfig = <IO(GPIO_IE(1))>;
			starfive,pin-gpio-dout = <GPO_SPI5_SSPFSSOUT>;
			starfive,pin-gpio-doen = <OEN_LOW>;
		};
	};

	ssp6_pins: ssp6-pins {
		ssp6-pins_tx {
			starfive,pins = <PAD_GPIO62>;
			starfive,pinmux = <PAD_GPIO62_FUNC_SEL 0>;
			starfive,pin-ioconfig = <IO(GPIO_IE(1))>;
			starfive,pin-gpio-dout = <GPO_SPI6_SSPTXD>;
			starfive,pin-gpio-doen = <OEN_LOW>;
		};

		ssp6-pins_rx {
			starfive,pins = <PAD_GPIO63>;
			starfive,pinmux = <PAD_GPIO63_FUNC_SEL 0>;
			starfive,pin-ioconfig = <IO(GPIO_IE(1))>;
			starfive,pin-gpio-doen = <OEN_HIGH>;
			starfive,pin-gpio-din =  <GPI_SPI6_SSPRXD>;
		};

		ssp6-pins_clk {
			starfive,pins = <PAD_GPIO60>;
			starfive,pinmux = <PAD_GPIO60_FUNC_SEL 0>;
			starfive,pin-ioconfig = <IO(GPIO_IE(1))>;
			starfive,pin-gpio-dout = <GPO_SPI6_SSPCLKOUT>;
			starfive,pin-gpio-doen = <OEN_LOW>;
		};

		ssp6-pins_cs {
			starfive,pins = <PAD_GPIO61>;
			starfive,pinmux = <PAD_GPIO61_FUNC_SEL 0>;
			starfive,pin-ioconfig = <IO(GPIO_IE(1))>;
			starfive,pin-gpio-dout = <GPO_SPI6_SSPFSSOUT>;
			starfive,pin-gpio-doen = <OEN_LOW>;
		};
	};

	dvp_pins: dvp-pins {
		dvp-clk-pins {
			starfive,pins = <PAD_GPIO21>;
			starfive,pinmux = <PAD_GPIO21_FUNC_SEL 2>;
			starfive,pin-ioconfig = <IO(GPIO_IE(1))>;
			starfive,padmux = <U0_SYS_CRG_DVP_CLK_FUNC_SEL 1>;
		};

		dvp-vsync-pins {
			starfive,pins = <PAD_GPIO22>;
			starfive,pinmux = <PAD_GPIO22_FUNC_SEL 2>;
			starfive,pin-ioconfig = <IO(GPIO_IE(1))>;
			starfive,padmux = <U0_DOM_ISP_TOP_U0_VIN_DVP_VVALID_C_FUNC_SEL 1>;
		};

		dvp-hsync-pins {
			starfive,pins = <PAD_GPIO23>;
			starfive,pinmux = <PAD_GPIO23_FUNC_SEL 2>;
			starfive,pin-ioconfig = <IO(GPIO_IE(1))>;
			starfive,padmux = <U0_DOM_ISP_TOP_U0_VIN_DVP_HVALID_C_FUNC_SEL 1>;
		};

		dvp-data0-pins {
			starfive,pins = <PAD_GPIO24>;
			starfive,pinmux = <PAD_GPIO24_FUNC_SEL 2>;
			starfive,pin-ioconfig = <IO(GPIO_IE(1))>;
			starfive,padmux = <U0_DOM_ISP_TOP_U0_VIN_DVP_DATA_C0_FUNC_SEL 1>;
		};

		dvp-data1-pins {
			starfive,pins = <PAD_GPIO25>;
			starfive,pinmux = <PAD_GPIO25_FUNC_SEL 2>;
			starfive,pin-ioconfig = <IO(GPIO_IE(1))>;
			starfive,padmux = <U0_DOM_ISP_TOP_U0_VIN_DVP_DATA_C1_FUNC_SEL 1>;
		};

		dvp-data2-pins {
			starfive,pins = <PAD_GPIO26>;
			starfive,pinmux = <PAD_GPIO26_FUNC_SEL 2>;
			starfive,pin-ioconfig = <IO(GPIO_IE(1))>;
			starfive,padmux = <U0_DOM_ISP_TOP_U0_VIN_DVP_DATA_C2_FUNC_SEL 1>;
		};

		dvp-data3-pins {
			starfive,pins = <PAD_GPIO27>;
			starfive,pinmux = <PAD_GPIO27_FUNC_SEL 2>;
			starfive,pin-ioconfig = <IO(GPIO_IE(1))>;
			starfive,padmux = <U0_DOM_ISP_TOP_U0_VIN_DVP_DATA_C3_FUNC_SEL 1>;
		};

		dvp-data4-pins {
			starfive,pins = <PAD_GPIO28>;
			starfive,pinmux = <PAD_GPIO28_FUNC_SEL 2>;
			starfive,pin-ioconfig = <IO(GPIO_IE(1))>;
			starfive,padmux = <U0_DOM_ISP_TOP_U0_VIN_DVP_DATA_C4_FUNC_SEL 1>;
		};

		dvp-data5-pins {
			starfive,pins = <PAD_GPIO29>;
			starfive,pinmux = <PAD_GPIO29_FUNC_SEL 2>;
			starfive,pin-ioconfig = <IO(GPIO_IE(1))>;
			starfive,padmux = <U0_DOM_ISP_TOP_U0_VIN_DVP_DATA_C5_FUNC_SEL 1>;
		};

		dvp-data6-pins {
			starfive,pins = <PAD_GPIO30>;
			starfive,pinmux = <PAD_GPIO30_FUNC_SEL 2>;
			starfive,pin-ioconfig = <IO(GPIO_IE(1))>;
			starfive,padmux = <U0_DOM_ISP_TOP_U0_VIN_DVP_DATA_C6_FUNC_SEL 1>;
		};

		dvp-data7-pins {
			starfive,pins = <PAD_GPIO31>;
			starfive,pinmux = <PAD_GPIO31_FUNC_SEL 2>;
			starfive,pin-ioconfig = <IO(GPIO_IE(1))>;
			starfive,padmux = <U0_DOM_ISP_TOP_U0_VIN_DVP_DATA_C7_FUNC_SEL 1>;
		};

		dvp-data8-pins {
			starfive,pins = <PAD_GPIO32>;
			starfive,pinmux = <PAD_GPIO32_FUNC_SEL 2>;
			starfive,pin-ioconfig = <IO(GPIO_IE(1))>;
			starfive,padmux = <U0_DOM_ISP_TOP_U0_VIN_DVP_DATA_C8_FUNC_SEL 1>;
		};

		dvp-data9-pins {
			starfive,pins = <PAD_GPIO33>;
			starfive,pinmux = <PAD_GPIO33_FUNC_SEL 2>;
			starfive,pin-ioconfig = <IO(GPIO_IE(1))>;
			starfive,padmux = <U0_DOM_ISP_TOP_U0_VIN_DVP_DATA_C9_FUNC_SEL 1>;
		};

		dvp-data10-pins {
			starfive,pins = <PAD_GPIO34>;
			starfive,pinmux = <PAD_GPIO34_FUNC_SEL 2>;
			starfive,pin-ioconfig = <IO(GPIO_IE(1))>;
			starfive,padmux = <U0_DOM_ISP_TOP_U0_VIN_DVP_DATA_C10_FUNC_SEL 1>;
		};

		dvp-data11-pins {
			starfive,pins = <PAD_GPIO35>;
			starfive,pinmux = <PAD_GPIO35_FUNC_SEL 2>;
			starfive,pin-ioconfig = <IO(GPIO_IE(1) | GPIO_PD(1))>;
			starfive,padmux = <U0_DOM_ISP_TOP_U0_VIN_DVP_DATA_C11_FUNC_SEL 1>;
		};
	};

	rgb_pad_pins: rgb-pad-pins {
		rgb-0-pins {
			starfive,pins = <PAD_GPIO36>;
			starfive,pinmux = <PAD_GPIO36_FUNC_SEL 1>;
			starfive,pin-ioconfig = <IO(GPIO_IE(0)|GPIO_SLEW(1)|GPIO_DS(3))>;
		};
		rgb-1-pins {
			starfive,pins = <PAD_GPIO37>;
			starfive,pinmux = <PAD_GPIO37_FUNC_SEL 1>;
			starfive,pin-ioconfig = <IO(GPIO_IE(0)|GPIO_DS(3))>;
		};

		rgb-2-pins {
			starfive,pins = <PAD_GPIO38>;
			starfive,pinmux = <PAD_GPIO38_FUNC_SEL 1>;
			starfive,pin-ioconfig = <IO(GPIO_IE(0)|GPIO_DS(3))>;
		};

		rgb-3-pins {
			starfive,pins = <PAD_GPIO39>;
			starfive,pinmux = <PAD_GPIO39_FUNC_SEL 1>;
			starfive,pin-ioconfig = <IO(GPIO_IE(0)|GPIO_DS(3))>;
		};
		rgb-4-pins {
			starfive,pins = <PAD_GPIO40>;
			starfive,pinmux = <PAD_GPIO40_FUNC_SEL 1>;
			starfive,pin-ioconfig = <IO(GPIO_IE(0)|GPIO_DS(3))>;
		};
		rgb-5-pins {
			starfive,pins = <PAD_GPIO41>;
			starfive,pinmux = <PAD_GPIO41_FUNC_SEL 1>;
			starfive,pin-ioconfig = <IO(GPIO_IE(0)|GPIO_DS(3))>;
		};
		rgb-6-pins {
			starfive,pins = <PAD_GPIO42>;
			starfive,pinmux = <PAD_GPIO42_FUNC_SEL 1>;
			starfive,pin-ioconfig = <IO(GPIO_IE(0)|GPIO_DS(3))>;
		};
		rgb-7-pins {
			starfive,pins = <PAD_GPIO43>;
			starfive,pinmux = <PAD_GPIO43_FUNC_SEL 1>;
			starfive,pin-ioconfig = <IO(GPIO_IE(0)|GPIO_DS(3))>;
		};

		rgb-8-pins {
			starfive,pins = <PAD_GPIO44>;
			starfive,pinmux = <PAD_GPIO44_FUNC_SEL 1>;
			starfive,pin-ioconfig = <IO(GPIO_IE(0)|GPIO_DS(3))>;
		};

		rgb-9-pins {
			starfive,pins = <PAD_GPIO45>;
			starfive,pinmux = <PAD_GPIO45_FUNC_SEL 1>;
			starfive,pin-ioconfig = <IO(GPIO_IE(0)|GPIO_DS(3))>;
		};
		rgb-10-pins {
			starfive,pins = <PAD_GPIO46>;
			starfive,pinmux = <PAD_GPIO46_FUNC_SEL 1>;
			starfive,pin-ioconfig = <IO(GPIO_IE(0)|GPIO_DS(3))>;
		};
		rgb-11-pins {
			starfive,pins = <PAD_GPIO47>;
			starfive,pinmux = <PAD_GPIO47_FUNC_SEL 1>;
			starfive,pin-ioconfig = <IO(GPIO_IE(0)|GPIO_DS(3))>;
		};
		rgb-12-pins {
			starfive,pins = <PAD_GPIO48>;
			starfive,pinmux = <PAD_GPIO48_FUNC_SEL 1>;
			starfive,pin-ioconfig = <IO(GPIO_IE(0)|GPIO_DS(3))>;
		};
		rgb-13-pins {
			starfive,pins = <PAD_GPIO49>;
			starfive,pinmux = <PAD_GPIO49_FUNC_SEL 1>;
			starfive,pin-ioconfig = <IO(GPIO_IE(0)|GPIO_DS(3))>;
		};
		rgb-14-pins {
			starfive,pins = <PAD_GPIO50>;
			starfive,pinmux = <PAD_GPIO50_FUNC_SEL 1>;
			starfive,pin-ioconfig = <IO(GPIO_IE(0)|GPIO_DS(3))>;
		};
		rgb-15-pins {
			starfive,pins = <PAD_GPIO51>;
			starfive,pinmux = <PAD_GPIO51_FUNC_SEL 1>;
			starfive,pin-ioconfig = <IO(GPIO_IE(0)|GPIO_DS(3))>;
		};
		rgb-16-pins {
			starfive,pins = <PAD_GPIO52>;
			starfive,pinmux = <PAD_GPIO52_FUNC_SEL 1>;
			starfive,pin-ioconfig = <IO(GPIO_IE(0)|GPIO_DS(3))>;
		};
		rgb-17-pins {
			starfive,pins = <PAD_GPIO53>;
			starfive,pinmux = <PAD_GPIO53_FUNC_SEL 1>;
			starfive,pin-ioconfig = <IO(GPIO_IE(0)|GPIO_DS(3))>;
		};
		rgb-18-pins {
			starfive,pins = <PAD_GPIO54>;
			starfive,pinmux = <PAD_GPIO54_FUNC_SEL 1>;
			starfive,pin-ioconfig = <IO(GPIO_IE(0)|GPIO_DS(3))>;
		};
		rgb-19-pins {
			starfive,pins = <PAD_GPIO55>;
			starfive,pinmux = <PAD_GPIO55_FUNC_SEL 1>;
			starfive,pin-ioconfig = <IO(GPIO_IE(0)|GPIO_DS(3))>;
		};
		rgb-20-pins {
			starfive,pins = <PAD_GPIO56>;
			starfive,pinmux = <PAD_GPIO56_FUNC_SEL 1>;
			starfive,pin-ioconfig = <IO(GPIO_IE(0)|GPIO_DS(3))>;
		};

		rgb-21-pins {
			starfive,pins = <PAD_GPIO57>;
			starfive,pinmux = <PAD_GPIO57_FUNC_SEL 1>;
			starfive,pin-ioconfig = <IO(GPIO_IE(0)|GPIO_DS(3))>;
		};
		rgb-22-pins {
			starfive,pins = <PAD_GPIO58>;
			starfive,pinmux = <PAD_GPIO58_FUNC_SEL 1>;
			starfive,pin-ioconfig = <IO(GPIO_IE(0)|GPIO_DS(3))>;
		};

		rgb-23-pins {
			starfive,pins = <PAD_GPIO59>;
			starfive,pinmux = <PAD_GPIO59_FUNC_SEL 1>;
			starfive,pin-ioconfig = <IO(GPIO_IE(0)|GPIO_DS(3))>;
		};
		rgb-24-pins {
			starfive,pins = <PAD_GPIO60>;
			starfive,pinmux = <PAD_GPIO60_FUNC_SEL 1>;
			starfive,pin-ioconfig = <IO(GPIO_IE(0)|GPIO_DS(3))>;
		};
		rgb-25-pins {
			starfive,pins = <PAD_GPIO61>;
			starfive,pinmux = <PAD_GPIO61_FUNC_SEL 1>;
			starfive,pin-ioconfig = <IO(GPIO_IE(0)|GPIO_DS(3))>;
		};
		rgb-26-pins {
			starfive,pins = <PAD_GPIO62>;
			starfive,pinmux = <PAD_GPIO62_FUNC_SEL 1>;
			starfive,pin-ioconfig = <IO(GPIO_IE(0)|GPIO_DS(3))>;
		};

		rgb-27-pins {
			starfive,pins = <PAD_GPIO63>;
			starfive,pinmux = <PAD_GPIO63_FUNC_SEL 1>;
			starfive,pin-ioconfig = <IO(GPIO_IE(0)|GPIO_DS(3))>;
		};

	};

	inno_hdmi_pins: inno_hdmi-pins {
		inno_hdmi-scl {
			starfive,pins = <PAD_GPIO7>;
			//starfive,pinmux = <PAD_GPIO7_FUNC_SEL 0>;
			starfive,pin-ioconfig = <IO(GPIO_IE(1) | (GPIO_PU(1)))>;
			starfive,pin-gpio-dout = <GPO_HDMI0_DDC_SCL_OUT>;
			starfive,pin-gpio-doen = <OEN_HDMI0_DDC_SCL_OEN>;
			starfive,pin-gpio-din =  <GPI_HDMI0_DDC_SCL_IN>;
		};

		inno_hdmi-sda {
			starfive,pins = <PAD_GPIO8>;
			//starfive,pinmux = <PAD_GPIO8_FUNC_SEL 0>;
			starfive,pin-ioconfig = <IO(GPIO_IE(1) | (GPIO_PU(1)))>;
			starfive,pin-gpio-dout = <GPO_HDMI0_DDC_SDA_OUT>;
			starfive,pin-gpio-doen = <OEN_HDMI0_DDC_SDA_OEN>;
			starfive,pin-gpio-din =  <GPI_HDMI0_DDC_SDA_IN>;
		};
		inno_hdmi-cec-pins {
			starfive,pins = <PAD_GPIO14>;
			//starfive,pinmux = <PAD_GPIO14_FUNC_SEL 0>;
			starfive,pin-ioconfig = <IO(GPIO_IE(1) | (GPIO_PU(1)))>;
			starfive,pin-gpio-doen = <OEN_HDMI0_CEC_SDA_OEN>;
			starfive,pin-gpio-dout = <GPO_HDMI0_CEC_SDA_OUT>;
			starfive,pin-gpio-din =  <GPI_HDMI0_CEC_SDA_IN>;
		};
		inno_hdmi-hpd-pins {
			starfive,pins = <PAD_GPIO15>;
			//starfive,pinmux = <PAD_GPIO15_FUNC_SEL 0>;
			starfive,pin-ioconfig = <IO(GPIO_IE(1))>;
			starfive,pin-gpio-doen = <OEN_HIGH>;
			starfive,pin-gpio-din =  <GPI_HDMI0_HPD>;
		};
	};

	mipitx_pins: mipitx-pins {
		mipitx-1-pins {
			starfive,pins = <PAD_GPIO36>;
			starfive,pinmux = <PAD_GPIO36_FUNC_SEL 1>;
			starfive,pin-ioconfig = <IO(GPIO_IE(0))>;
		};
		mipitx-2-pins {
			starfive,pins = <PAD_GPIO37>;
			starfive,pinmux = <PAD_GPIO37_FUNC_SEL 1>;
			starfive,pin-ioconfig = <IO(GPIO_IE(0))>;
		};

		mipitx-3-pins {
			starfive,pins = <PAD_GPIO38>;
			starfive,pinmux = <PAD_GPIO38_FUNC_SEL 1>;
			starfive,pin-ioconfig = <IO(GPIO_IE(0))>;
		};

		mipitx-4-pins {
			starfive,pins = <PAD_GPIO39>;
			starfive,pinmux = <PAD_GPIO39_FUNC_SEL 1>;
			starfive,pin-ioconfig = <IO(GPIO_IE(0))>;
		};
		mipitx-5-pins {
			starfive,pins = <PAD_GPIO40>;
			starfive,pinmux = <PAD_GPIO40_FUNC_SEL 1>;
			starfive,pin-ioconfig = <IO(GPIO_IE(0))>;
		};
	};

	pcie0_perst_default: pcie0_perst_default {
		perst-pins {
			starfive,pins = <PAD_GPIO26>;
			starfive,pinmux = <PAD_GPIO26_FUNC_SEL 0>;
			starfive,pin-ioconfig = <IO(GPIO_IE(1))>;
			starfive,pin-gpio-dout = <GPO_HIGH>;
			starfive,pin-gpio-doen = <OEN_LOW>;
		};
	};

	pcie0_perst_active: pcie0_perst_active {
		perst-pins {
			starfive,pins = <PAD_GPIO26>;
			starfive,pinmux = <PAD_GPIO26_FUNC_SEL 0>;
			starfive,pin-ioconfig = <IO(GPIO_IE(1))>;
			starfive,pin-gpio-dout = <GPO_LOW>;
			starfive,pin-gpio-doen = <OEN_LOW>;
		};
	};

	pcie0_power_default: pcie0_power_default {
		power-pins {
			starfive,pins = <PAD_GPIO32>;
			starfive,pinmux = <PAD_GPIO32_FUNC_SEL 0>;
			starfive,pin-ioconfig = <IO(GPIO_IE(1))>;
			starfive,pin-gpio-dout = <GPO_LOW>;
			starfive,pin-gpio-doen = <OEN_LOW>;
		};
	};

	pcie0_power_active: pcie0_power_active {
		power-pins {
			starfive,pins = <PAD_GPIO32>;
			starfive,pinmux = <PAD_GPIO32_FUNC_SEL 0>;
			starfive,pin-ioconfig = <IO(GPIO_IE(1))>;
			starfive,pin-gpio-dout = <GPO_HIGH>;
			starfive,pin-gpio-doen = <OEN_LOW>;
		};
	};

	pcie1_perst_default: pcie1_perst_default {
		perst-pins {
			starfive,pins = <PAD_GPIO28>;
			starfive,pinmux = <PAD_GPIO28_FUNC_SEL 0>;
			starfive,pin-ioconfig = <IO(GPIO_IE(1))>;
			starfive,pin-gpio-dout = <GPO_HIGH>;
			starfive,pin-gpio-doen = <OEN_LOW>;
		};
	};

	pcie1_perst_active: pcie1_perst_active {
		perst-pins {
			starfive,pins = <PAD_GPIO28>;
			starfive,pinmux = <PAD_GPIO28_FUNC_SEL 0>;
			starfive,pin-ioconfig = <IO(GPIO_IE(1))>;
			starfive,pin-gpio-dout = <GPO_LOW>;
			starfive,pin-gpio-doen = <OEN_LOW>;
		};
	};

	pcie1_power_default: pcie1_power_default {
		power-pins {
			starfive,pins = <PAD_GPIO21>;
			starfive,pinmux = <PAD_GPIO21_FUNC_SEL 0>;
			starfive,pin-ioconfig = <IO(GPIO_IE(1))>;
			starfive,pin-gpio-dout = <GPO_LOW>;
			starfive,pin-gpio-doen = <OEN_LOW>;
		};
	};

	pcie1_power_active: pcie1_power_active {
		power-pins {
			starfive,pins = <PAD_GPIO21>;
			starfive,pinmux = <PAD_GPIO21_FUNC_SEL 0>;
			starfive,pin-ioconfig = <IO(GPIO_IE(1))>;
			starfive,pin-gpio-dout = <GPO_HIGH>;
			starfive,pin-gpio-doen = <OEN_LOW>;
		};
	};

	usb_pins: usb-pins {
		drive-vbus-pin {
			starfive,pins = <PAD_GPIO33>;
			starfive,pinmux = <PAD_GPIO33_FUNC_SEL 0>;
			starfive,pin-ioconfig = <IO(GPIO_IE(1))>;
			starfive,pin-gpio-dout = <GPO_HIGH>;
			starfive,pin-gpio-doen = <OEN_LOW>;
		};

		overcurrent-pin {
			starfive,pins = <PAD_GPIO34>;
			starfive,pinmux = <PAD_GPIO34_FUNC_SEL 0>;
			starfive,pin-ioconfig = <IO(GPIO_IE(1))>;
			starfive,pin-gpio-din = <GPI_USB0_OVERCURRENT_N_IO>;
			starfive,pin-gpio-doen = <OEN_HIGH>;
		};
	};

	mclk_ext_pins: mclk_ext_pins {
		mclk_ext_pins {
			starfive,pins = <PAD_GPIO4>;
			starfive,pin-ioconfig = <IO(GPIO_IE(1))>;
			starfive,pin-gpio-din = <GPI_CRG0_EXT_MCLK>;
			starfive,pin-gpio-doen = <OEN_HIGH>;
		};
	};
};

&gpioa {
	pwm_ch4to5_pins: pwm-ch4to5-pins {
		pwm-ch4-pins {
			starfive,pins = <PAD_RGPIO0>;
			starfive,pin-ioconfig = <IO(GPIO_IE(1))>;
			starfive,pin-gpio-dout = <U0_PWM_8CH_PTC_PWM_4>;
			starfive,pin-gpio-doen = <U0_PWM_8CH_PTC_OE_N_4>;
		};

		pwm-ch5-pins {
			starfive,pins = <PAD_RGPIO1>;
			starfive,pin-ioconfig = <IO(GPIO_IE(1))>;
			starfive,pin-gpio-dout = <U0_PWM_8CH_PTC_PWM_5>;
			starfive,pin-gpio-doen = <U0_PWM_8CH_PTC_OE_N_5>;
		};
	};

	pwm_ch6to7_pins: pwm-ch6to7-pins {
		pwm-ch6-pins {
			starfive,pins = <PAD_RGPIO0>;
			starfive,pin-ioconfig = <IO(GPIO_IE(1))>;
			starfive,pin-gpio-dout = <U0_PWM_8CH_PTC_PWM_6>;
			starfive,pin-gpio-doen = <U0_PWM_8CH_PTC_OE_N_6>;
		};

		pwm-ch7-pins {
			starfive,pins = <PAD_RGPIO1>;
			starfive,pin-ioconfig = <IO(GPIO_IE(1))>;
			starfive,pin-gpio-dout = <U0_PWM_8CH_PTC_PWM_7>;
			starfive,pin-gpio-doen = <U0_PWM_8CH_PTC_OE_N_7>;
		};
	};
};
